# bypass_pnr_reg_sp: IP-XACT component
VLNV Vendor:Library:bypass_pnr_reg_sp:1.0

## Address spaces and blocks
bypass_pnr_reg_sp.bypass_pnr_reg_sp_block: base 0x0, range 0x4, width 32, register

## Registers
Registers are 32-bit, read-write, no defined reset value unless marked. A register's access mark holds for its fields unless they carry their own. Offsets are from the block's base; lines under a group give offsets from that group; [hi:lo] are bit positions; {n}, {i} and the like mark numbered series; 'fields as' and 'values as' point back to an identical list; <NAME> marks a mode.

## bypass_pnr_reg_sp.bypass_pnr_reg_sp_block
Base 0x00000000
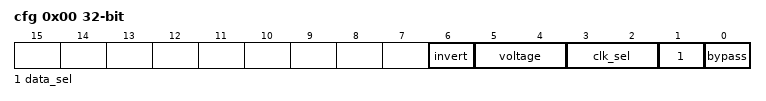
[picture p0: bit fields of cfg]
0x00 cfg — csr_reg_desc
  [6] invert
  [5:4] voltage
  [3:2] clk_sel — 00: CLK0 01: CLK1 10: CLK2 11: CLK3
  [1] data_sel — 0: A 1: B
  [0] bypass — 0: BYPASS 1: REG
